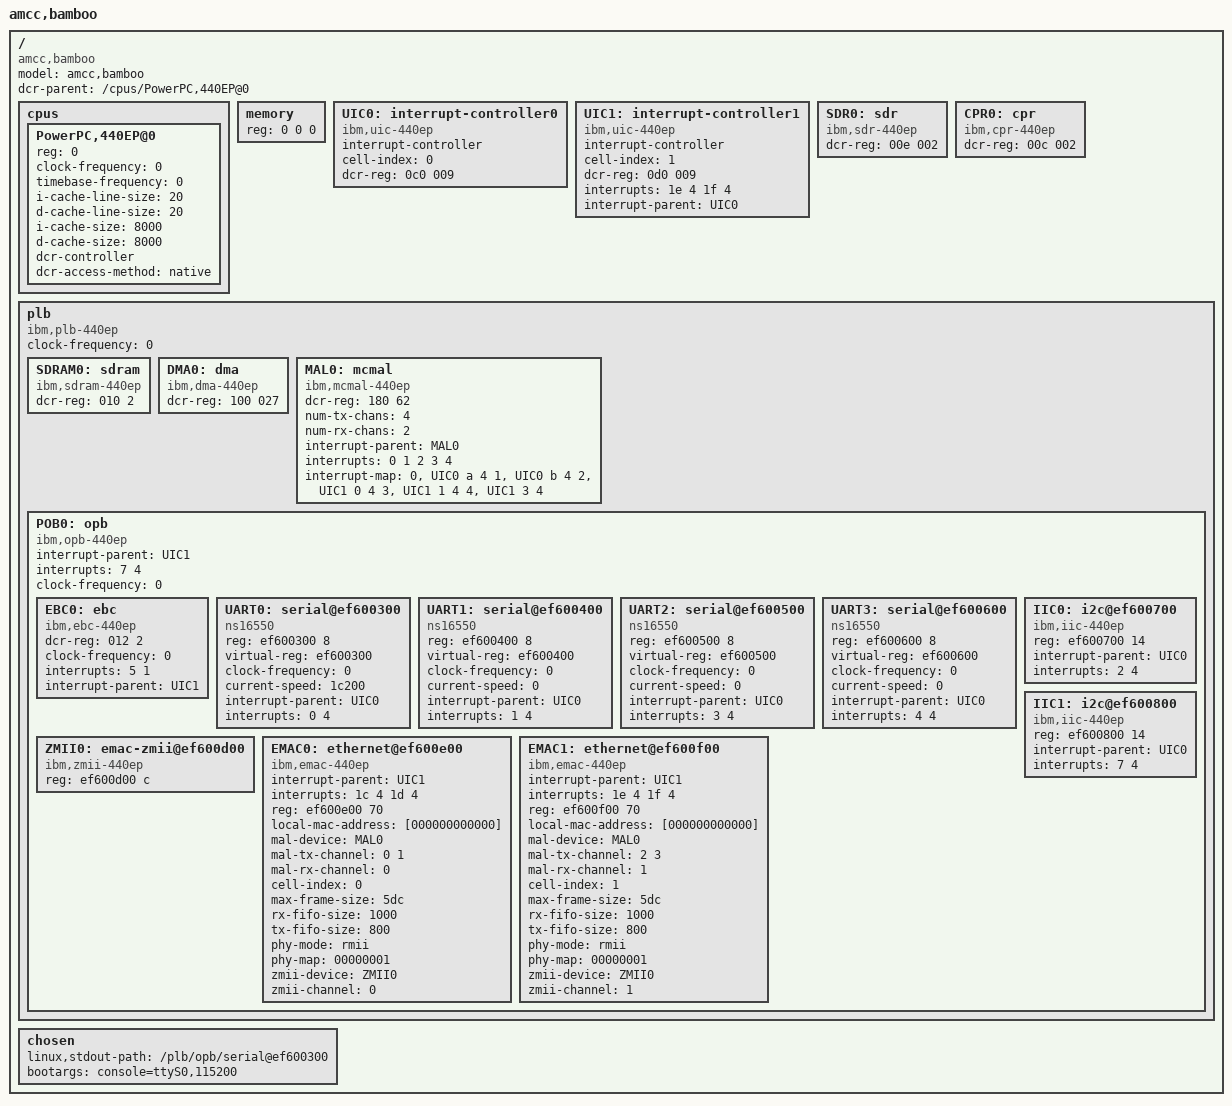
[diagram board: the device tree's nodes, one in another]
/*
 * Device Tree Source for AMCC Bamboo
 *
 * Copyright (c) 2006, 2007 IBM Corp.
 * Josh Boyer <jwboyer@linux.vnet.ibm.com>
 *
 * FIXME: Draft only!
 *
 * This file is licensed under the terms of the GNU General Public
 * License version 2.  This program is licensed "as is" without
 * any warranty of any kind, whether express or implied.
 */

/ {
	#address-cells = <2>;
	#size-cells = <1>;
	model = "amcc,bamboo";
	compatible = "amcc,bamboo";
	dcr-parent = <&/cpus/PowerPC,440EP@0>;

	cpus {
		#address-cells = <1>;
		#size-cells = <0>;

		PowerPC,440EP@0 {
			device_type = "cpu";
			reg = <0>;
			clock-frequency = <0>; /* Filled in by zImage */
			timebase-frequency = <0>; /* Filled in by zImage */
			i-cache-line-size = <20>;
			d-cache-line-size = <20>;
			i-cache-size = <8000>;
			d-cache-size = <8000>;
			dcr-controller;
			dcr-access-method = "native";
		};
	};

	memory {
		device_type = "memory";
		reg = <0 0 0>; /* Filled in by zImage */
	};

	UIC0: interrupt-controller0 {
		compatible = "ibm,uic-440ep","ibm,uic";
		interrupt-controller;
		cell-index = <0>;
		dcr-reg = <0c0 009>;
		#address-cells = <0>;
		#size-cells = <0>;
		#interrupt-cells = <2>;
	};

	UIC1: interrupt-controller1 {
		compatible = "ibm,uic-440ep","ibm,uic";
		interrupt-controller;
		cell-index = <1>;
		dcr-reg = <0d0 009>;
		#address-cells = <0>;
		#size-cells = <0>;
		#interrupt-cells = <2>;
		interrupts = <1e 4 1f 4>; /* cascade */
		interrupt-parent = <&UIC0>;
	};

	SDR0: sdr {
		compatible = "ibm,sdr-440ep";
		dcr-reg = <00e 002>;
	};

	CPR0: cpr {
		compatible = "ibm,cpr-440ep";
		dcr-reg = <00c 002>;
	};

	plb {
		compatible = "ibm,plb-440ep", "ibm,plb-440gp", "ibm,plb4";
		#address-cells = <2>;
		#size-cells = <1>;
		ranges;
		clock-frequency = <0>; /* Filled in by zImage */

		SDRAM0: sdram {
			compatible = "ibm,sdram-440ep", "ibm,sdram-405gp";
			dcr-reg = <010 2>;
		};

		DMA0: dma {
			compatible = "ibm,dma-440ep", "ibm,dma-440gp";
			dcr-reg = <100 027>;
		};

		MAL0: mcmal {
			compatible = "ibm,mcmal-440ep", "ibm,mcmal-440gp", "ibm,mcmal";
			dcr-reg = <180 62>;
			num-tx-chans = <4>;
			num-rx-chans = <2>;
			interrupt-parent = <&MAL0>;
			interrupts = <0 1 2 3 4>;
			#interrupt-cells = <1>;
			interrupt-map = </*TXEOB*/ 0 &UIC0 a 4
					/*RXEOB*/ 1 &UIC0 b 4
					/*SERR*/  2 &UIC1 0 4
					/*TXDE*/  3 &UIC1 1 4
					/*RXDE*/  4 &UIC1 3 4>;
		};

		POB0: opb {
		  	compatible = "ibm,opb-440ep", "ibm,opb-440gp", "ibm,opb";
			#address-cells = <1>;
			#size-cells = <1>;
			/* Bamboo is oddball in the 44x world and doesn't use the ERPN
			 * bits.
			 */
		  	ranges = <00000000 0 00000000 80000000
			          80000000 0 80000000 80000000>;
		  	interrupt-parent = <&UIC1>;
		  	interrupts = <7 4>;
		  	clock-frequency = <0>; /* Filled in by zImage */

			EBC0: ebc {
				compatible = "ibm,ebc-440ep", "ibm,ebc-440gp", "ibm,ebc";
				dcr-reg = <012 2>;
				#address-cells = <2>;
				#size-cells = <1>;
				clock-frequency = <0>; /* Filled in by zImage */
				ranges;
				interrupts = <5 1>;
				interrupt-parent = <&UIC1>;
			};

			UART0: serial@ef600300 {
		   		device_type = "serial";
		   		compatible = "ns16550";
		   		reg = <ef600300 8>;
		   		virtual-reg = <ef600300>;
		   		clock-frequency = <0>; /* Filled in by zImage */
		   		current-speed = <1c200>;
		   		interrupt-parent = <&UIC0>;
		   		interrupts = <0 4>;
	   		};

			UART1: serial@ef600400 {
		   		device_type = "serial";
		   		compatible = "ns16550";
		   		reg = <ef600400 8>;
		   		virtual-reg = <ef600400>;
		   		clock-frequency = <0>;
		   		current-speed = <0>;
		   		interrupt-parent = <&UIC0>;
		   		interrupts = <1 4>;
	   		};

			UART2: serial@ef600500 {
		   		device_type = "serial";
		   		compatible = "ns16550";
		   		reg = <ef600500 8>;
		   		virtual-reg = <ef600500>;
		   		clock-frequency = <0>;
		   		current-speed = <0>;
		   		interrupt-parent = <&UIC0>;
		   		interrupts = <3 4>;
	   		};

			UART3: serial@ef600600 {
		   		device_type = "serial";
		   		compatible = "ns16550";
		   		reg = <ef600600 8>;
		   		virtual-reg = <ef600600>;
		   		clock-frequency = <0>;
		   		current-speed = <0>;
		   		interrupt-parent = <&UIC0>;
		   		interrupts = <4 4>;
	   		};

			IIC0: i2c@ef600700 {
				device_type = "i2c";
				compatible = "ibm,iic-440ep", "ibm,iic-440gp", "ibm,iic";
				reg = <ef600700 14>;
				interrupt-parent = <&UIC0>;
				interrupts = <2 4>;
			};

			IIC1: i2c@ef600800 {
				device_type = "i2c";
				compatible = "ibm,iic-440ep", "ibm,iic-440gp", "ibm,iic";
				reg = <ef600800 14>;
				interrupt-parent = <&UIC0>;
				interrupts = <7 4>;
			};

			ZMII0: emac-zmii@ef600d00 {
				device_type = "zmii-interface";
				compatible = "ibm,zmii-440ep", "ibm,zmii-440gp", "ibm,zmii";
				reg = <ef600d00 c>;
			};

			EMAC0: ethernet@ef600e00 {
				device_type = "network";
				compatible = "ibm,emac-440ep", "ibm,emac-440gp", "ibm,emac";
				interrupt-parent = <&UIC1>;
				interrupts = <1c 4 1d 4>;
				reg = <ef600e00 70>;
				local-mac-address = [000000000000];
				mal-device = <&MAL0>;
				mal-tx-channel = <0 1>;
				mal-rx-channel = <0>;
				cell-index = <0>;
				max-frame-size = <5dc>;
				rx-fifo-size = <1000>;
				tx-fifo-size = <800>;
				phy-mode = "rmii";
				phy-map = <00000001>;
				zmii-device = <&ZMII0>;
				zmii-channel = <0>;
			};

			EMAC1: ethernet@ef600f00 {
				device_type = "network";
				compatible = "ibm,emac-440ep", "ibm,emac-440gp", "ibm,emac";
				interrupt-parent = <&UIC1>;
				interrupts = <1e 4 1f 4>;
				reg = <ef600f00 70>;
				local-mac-address = [000000000000];
				mal-device = <&MAL0>;
				mal-tx-channel = <2 3>;
				mal-rx-channel = <1>;
				cell-index = <1>;
				max-frame-size = <5dc>;
				rx-fifo-size = <1000>;
				tx-fifo-size = <800>;
				phy-mode = "rmii";
				phy-map = <00000001>;
				zmii-device = <&ZMII0>;
				zmii-channel = <1>;
			};
		};
	};

	chosen {
		linux,stdout-path = "/plb/opb/serial@ef600300";
		bootargs = "console=ttyS0,115200";
	};
};
